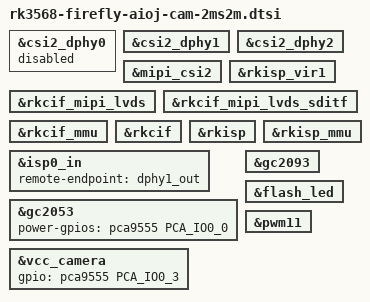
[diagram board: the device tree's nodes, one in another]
// SPDX-License-Identifier: (GPL-2.0+ OR MIT)
/*
 * Copyright (c) 2020 Rockchip Electronics Co., Ltd.
 *
 */

/* 2M  dual camera gc2053(IR)/gc2093(RGB) */

/*
* csi2_dphy0: used for csi2 dphy full mode,
        is mutually exclusive with
        csi2_dphy1 and csi2_dphy2
* csi2_dphy1: used for csi2 dphy split mode,
        physical lanes use lane0 and lane1,
        can be used with csi2_dphy2  parallel
* csi2_dphy2: used for csi2 dphy split mode,
        physical lanes use lane2 and lane3,
        can be used with csi2_dphy1  parallel
*/

&csi2_dphy0 {
    status = "disabled";
};

&csi2_dphy1 {
    status = "okay";
};


&csi2_dphy2 {
    status = "okay";
};

&mipi_csi2 {
    status = "okay";
};

&rkisp_vir1 {
    status = "okay";
};

&mipi_csi2 {
    status = "okay";
};

&rkcif_mipi_lvds {
    status = "okay";
};

&rkcif_mipi_lvds_sditf {
    status = "okay";
};

&rkcif_mmu {
    status = "okay";
};

&rkcif {
    status = "okay";
};

&rkisp {
    status = "okay";
};

&rkisp_mmu {
    status = "okay";
};

/*
 * csidphy_out ----> csi2_dphy0
 * dphy1_out   ----> csi2_dphy1
 * dphy2_out   ----> csi2_dphy2
 */
&isp0_in {
    remote-endpoint = <&dphy1_out>;
};

&gc2053 {
    power-gpios = <&pca9555 PCA_IO0_0 GPIO_ACTIVE_HIGH>; //IR_PWR_EN
    status = "okay";
};

&gc2093 {
    status = "okay";
};

&vcc_camera {
    gpio = <&pca9555 PCA_IO0_3 GPIO_ACTIVE_HIGH>;
    status = "okay";
};

&flash_led {
    status = "okay";
};


&pwm11 {
	status = "okay";
};

